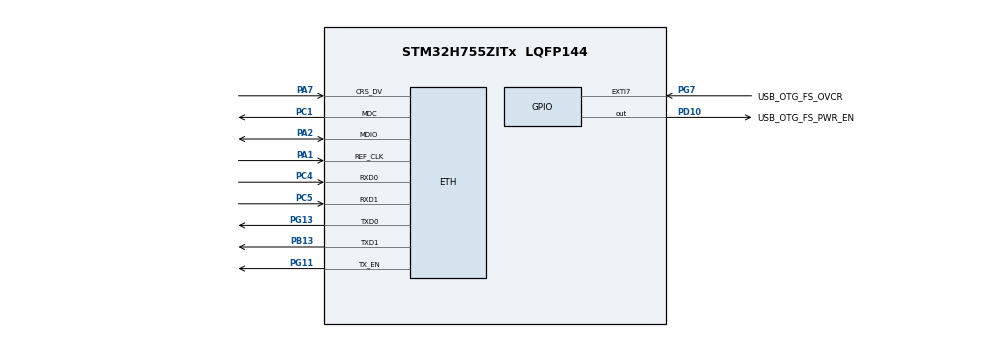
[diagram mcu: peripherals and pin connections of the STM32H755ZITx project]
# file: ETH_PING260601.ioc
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CortexM4.IPs=FATFS_M4\:I,FREERTOS_M4\:I,IWDG2\:I,RCC,WWDG2\:I,DMA,BDMA,MDMA,NVIC2\:I,ETH\:I,DEBUG,PDM2PCM_M4\:I,PWR,RESMGR_UTILITY,SYS_M4\:I,USB_DEVICE_M4\:I,USB_HOST_M4\:I,CORTEX_M4\:I,GPIO,OPENAMP_M4\:I,VREFBUF,NUCLEO-H755ZI-Q,LWIP\:I
CortexM7.IPs=FATFS_M7\:I,FREERTOS_M7\:I,IWDG1\:I,RCC\:I,WWDG1\:I,DMA\:I,BDMA\:I,MDMA\:I,NVIC1\:I,USB_OTG_FS\:I,USB_OTG_FS1\:I,SYS\:I,CORTEX_M7\:I,DEBUG\:I,PDM2PCM_M7\:I,PWR\:I,RESMGR_UTILITY\:I,USB_DEVICE_M7\:I,USB_HOST_M7\:I,GPIO\:I,OPENAMP_M7\:I,VREFBUF\:I,NUCLEO-H755ZI-Q\:I
ETH.MediaInterface=HAL_ETH_RMII_MODE
LWIP.BSP.number=1
LWIP.GATEWAY_ADDRESS=192.168.088.001
LWIP.IP_ADDRESS=192.168.088.010
LWIP.LWIP_DHCP=0
LWIP.NETMASK_ADDRESS=255.255.255.000
LWIP.TCP_MSS=1460
LWIP.TCP_SND_QUEUELEN=16
LWIP.Version=v2.2.1_Cube
LWIP0.BSP.STBoard=false
LWIP0.BSP.api=BSP_COMPONENT_DRIVER
LWIP0.BSP.component=LAN8742
LWIP0.BSP.instance=LAN8742
LWIP0.BSP.name=Driver_PHY
LWIP0.BSP.semaphore=S_LAN8742
LWIP0.BSP.solution=LAN8742
Mcu.Family=STM32H7
Mcu.Name=STM32H755ZITx
Mcu.Package=LQFP144
NUCLEO-H755ZI-Q.BUTTON=1
NUCLEO-H755ZI-Q.LD1=true
NUCLEO-H755ZI-Q.LD2=true
NUCLEO-H755ZI-Q.LD3=true
NUCLEO-H755ZI-Q.VCP=true
NVIC1.EXTI15_10_IRQn=true\:0\:0\:false\:false\:true\:false\:true\:true
NVIC1.PriorityGroup=NVIC_PRIORITYGROUP_4
NVIC2.ETH_IRQn=true\:0\:0\:false\:false\:true\:true\:true\:true
NVIC2.PriorityGroup=NVIC_PRIORITYGROUP_4
PA1.GPIO_Speed_Default_HIGH=GPIO_SPEED_FREQ_VERY_HIGH
PA1.Mode=RMII
PA1.PinAttribute=CortexM4
PA1.Signal=ETH_REF_CLK
PA11.PinAttribute=CortexM7
PA11.Signal=USB_OTG_FS_DM
PA12.PinAttribute=CortexM7
PA12.Signal=USB_OTG_FS_DP
PA2.GPIO_Speed_Default_HIGH=GPIO_SPEED_FREQ_VERY_HIGH
PA2.Mode=RMII
PA2.PinAttribute=CortexM4
PA2.Signal=ETH_MDIO
PA7.GPIO_Speed_Default_HIGH=GPIO_SPEED_FREQ_VERY_HIGH
PA7.Mode=RMII
PA7.PinAttribute=CortexM4
PA7.Signal=ETH_CRS_DV
PA8.PinAttribute=CortexM7
PA8.Signal=USB_OTG_FS_SOF
PA9.PinAttribute=CortexM7
PA9.Signal=USB_OTG_FS_VBUS
PB13.GPIO_Speed_Default_HIGH=GPIO_SPEED_FREQ_VERY_HIGH
PB13.Mode=RMII
PB13.PinAttribute=CortexM4
PB13.Signal=ETH_TXD1
PC1.GPIO_Speed_Default_HIGH=GPIO_SPEED_FREQ_VERY_HIGH
PC1.Mode=RMII
PC1.PinAttribute=CortexM4
PC1.Signal=ETH_MDC
PC14-OSC32_IN\ (OSC32_IN).Mode=LSE-External-Oscillator
PC14-OSC32_IN\ (OSC32_IN).PinAttribute=Free
PC14-OSC32_IN\ (OSC32_IN).Signal=RCC_OSC32_IN
PC15-OSC32_OUT\ (OSC32_OUT).Mode=LSE-External-Oscillator
PC15-OSC32_OUT\ (OSC32_OUT).PinAttribute=Free
PC15-OSC32_OUT\ (OSC32_OUT).Signal=RCC_OSC32_OUT
PC4.GPIO_Speed_Default_HIGH=GPIO_SPEED_FREQ_VERY_HIGH
PC4.Mode=RMII
PC4.PinAttribute=CortexM4
PC4.Signal=ETH_RXD0
PC5.GPIO_Speed_Default_HIGH=GPIO_SPEED_FREQ_VERY_HIGH
PC5.Mode=RMII
PC5.PinAttribute=CortexM4
PC5.Signal=ETH_RXD1
PD10.GPIO_Label=USB_OTG_FS_PWR_EN
PD10.PinAttribute=Free
PD10.Signal=GPIO_Output
PD8.Signal=USART3_TX
PD9.Signal=USART3_RX
PG11.GPIO_Speed_Default_HIGH=GPIO_SPEED_FREQ_VERY_HIGH
PG11.Mode=RMII
PG11.PinAttribute=CortexM4
PG11.Signal=ETH_TX_EN
PG13.GPIO_Speed_Default_HIGH=GPIO_SPEED_FREQ_VERY_HIGH
PG13.Mode=RMII
PG13.PinAttribute=CortexM4
PG13.Signal=ETH_TXD0
PG7.GPIO_Label=USB_OTG_FS_OVCR
PG7.PinAttribute=Free
PG7.Signal=GPXTI7
PH0-OSC_IN\ (PH0).Mode=HSE-External-Clock-Source
PH0-OSC_IN\ (PH0).PinAttribute=Free
PH0-OSC_IN\ (PH0).Signal=RCC_OSC_IN
PH1-OSC_OUT\ (PH1).PinAttribute=Free
PH1-OSC_OUT\ (PH1).Signal=RCC_OSC_OUT
ProjectManager.HeapSize=M4-0x200,M7-0x200
ProjectManager.StackSize=M4-0x400,M7-0x400
ProjectManager.TargetToolchain=STM32CubeIDE
RCC.ADCFreq_Value=50390625
RCC.APB1Freq_Value=120000000
RCC.APB2Freq_Value=120000000
RCC.APB3Freq_Value=120000000
RCC.APB4Freq_Value=120000000
RCC.CortexFreq_Value=120000000
RCC.DIVM1=5
RCC.DIVN1=48
RCC.DIVQ1=5
RCC.HCLKFreq_Value=120000000
RCC.PLL2FRACN=0
RCC.PLL3FRACN=0
RCC.PLLFRACN=0
RCC.PLLSourceVirtual=RCC_PLLSOURCE_HSE
RCC.SYSCLKFreq_VALUE=120000000
RCC.SYSCLKSource=RCC_SYSCLKSOURCE_PLLCLK
RCC.SupplySource=PWR_DIRECT_SMPS_SUPPLY
RCC.USBFreq_Value=48000000
VP_LWIP_VS_Enabled.Mode=Enabled
VP_NUCLEO-H755ZI-Q_VS_BSP_COMMON.Mode=COMMON
VP_SYS_M4_VS_Systick.Mode=SysTick
board=NUCLEO-H755ZI-Q

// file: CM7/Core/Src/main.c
/* USER CODE BEGIN Header */
/**
  ******************************************************************************
  * @file           : main.c
  * @brief          : Main program body
  ******************************************************************************
  * @attention
  *
  * Copyright (c) 2026 STMicroelectronics.
  * All rights reserved.
  *
  * This software is licensed under terms that can be found in the LICENSE file
  * in the root directory of this software component.
  * If no LICENSE file comes with this software, it is provided AS-IS.
  *
  ******************************************************************************
  */
/* USER CODE END Header */
#include "main.h"

/* USER CODE BEGIN PD */

/* DUAL_CORE_BOOT_SYNC_SEQUENCE: Define for dual core boot synchronization    */
/*                             demonstration code based on hardware semaphore */
/* This define is present in both CM7/CM4 projects                            */
/* To comment when developping/debugging on a single core                     */
#define DUAL_CORE_BOOT_SYNC_SEQUENCE

#if defined(DUAL_CORE_BOOT_SYNC_SEQUENCE)
#ifndef HSEM_ID_0
#define HSEM_ID_0 (0U) /* HW semaphore 0*/
#endif
#endif /* DUAL_CORE_BOOT_SYNC_SEQUENCE */

/* USER CODE END PD */

COM_InitTypeDef BspCOMInit;

void SystemClock_Config(void);
static void MX_GPIO_Init(void);

int main(void)
{

/* USER CODE BEGIN Boot_Mode_Sequence_0 */
#if defined(DUAL_CORE_BOOT_SYNC_SEQUENCE)
  int32_t timeout;
#endif /* DUAL_CORE_BOOT_SYNC_SEQUENCE */
/* USER CODE END Boot_Mode_Sequence_0 */

/* USER CODE BEGIN Boot_Mode_Sequence_1 */
#if defined(DUAL_CORE_BOOT_SYNC_SEQUENCE)
  /* Wait until CPU2 boots and enters in stop mode or timeout*/
  timeout = 0xFFFF;
  while((__HAL_RCC_GET_FLAG(RCC_FLAG_D2CKRDY) != RESET) && (timeout-- > 0));
  if ( timeout < 0 )
  {
  Error_Handler();
  }
#endif /* DUAL_CORE_BOOT_SYNC_SEQUENCE */
/* USER CODE END Boot_Mode_Sequence_1 */
  /* MCU Configuration--------------------------------------------------------*/

  /* Reset of all peripherals, Initializes the Flash interface and the Systick. */
  HAL_Init();

  /* USER CODE BEGIN Init */
  //SCB_EnableICache();
  //SCB_EnableDCache();
  /* USER CODE END Init */

  /* Configure the system clock */
  SystemClock_Config();
/* USER CODE BEGIN Boot_Mode_Sequence_2 */
#if defined(DUAL_CORE_BOOT_SYNC_SEQUENCE)
/* When system initialization is finished, Cortex-M7 will release Cortex-M4 by means of
HSEM notification */
/*HW semaphore Clock enable*/
__HAL_RCC_HSEM_CLK_ENABLE();
/*Take HSEM */
HAL_HSEM_FastTake(HSEM_ID_0);
/*Release HSEM in order to notify the CPU2(CM4)*/
HAL_HSEM_Release(HSEM_ID_0,0);
/* wait until CPU2 wakes up from stop mode */
timeout = 0xFFFF;
while((__HAL_RCC_GET_FLAG(RCC_FLAG_D2CKRDY) == RESET) && (timeout-- > 0));
if ( timeout < 0 )
{
Error_Handler();
}
#endif /* DUAL_CORE_BOOT_SYNC_SEQUENCE */
/* USER CODE END Boot_Mode_Sequence_2 */

  /* USER CODE BEGIN SysInit */

  // 喚醒 Cortex-M4 核心
  HAL_PWREx_ReleaseCore(PWR_CORE_CPU2);// 這是重點
  /* USER CODE END SysInit */

  /* Initialize all configured peripherals */
  MX_GPIO_Init();

  /* Initialize leds */
  //BSP_LED_Init(LED_GREEN); //由 CM4 自己控制 LED  2026-06-02 09:46:01
  //BSP_LED_Init(LED_YELLOW);
  //BSP_LED_Init(LED_RED);

  /* Initialize USER push-button, will be used to trigger an interrupt each time it's pressed.*/
  BSP_PB_Init(BUTTON_USER, BUTTON_MODE_EXTI);

  /* Initialize COM1 port (115200, 8 bits (7-bit data + 1 stop bit), no parity */
  BspCOMInit.BaudRate   = 115200;
  BspCOMInit.WordLength = COM_WORDLENGTH_8B;
  BspCOMInit.StopBits   = COM_STOPBITS_1;
  BspCOMInit.Parity     = COM_PARITY_NONE;
  BspCOMInit.HwFlowCtl  = COM_HWCONTROL_NONE;
  if (BSP_COM_Init(COM1, &BspCOMInit) != BSP_ERROR_NONE)
  {
    Error_Handler();
  }

  /* ------------------ CRITICAL MODIFICATION BEGIN ------------------ */

  // 1. 啟用 SYSCFG 時脈（SYSCFG 位於 APB4 總線，控制了全晶片的引腳網路模式切換）
  __HAL_RCC_SYSCFG_CLK_ENABLE();

  // 2. 強制將乙太網路硬體介面切換為 RMII 模式。
  //    這行硬體設定必須在 CM4 核心啟動並初始化網路之前，由 CM7 先行在底層組態完成！
  HAL_SYSCFG_ETHInterfaceSelect(SYSCFG_ETH_RMII);

  /* ------------------- CRITICAL MODIFICATION END ------------------- */

  /* Infinite loop */
  while (1)
  {

  }
}

void SystemClock_Config(void)
{
  RCC_OscInitTypeDef RCC_OscInitStruct = {0};
  RCC_ClkInitTypeDef RCC_ClkInitStruct = {0};

  /** Supply configuration update enable
  */
  HAL_PWREx_ConfigSupply(PWR_DIRECT_SMPS_SUPPLY);

  /** Configure the main internal regulator output voltage
  */
  __HAL_PWR_VOLTAGESCALING_CONFIG(PWR_REGULATOR_VOLTAGE_SCALE3);

  while(!__HAL_PWR_GET_FLAG(PWR_FLAG_VOSRDY)) {}

  /** Initializes the RCC Oscillators according to the specified parameters
  * in the RCC_OscInitTypeDef structure.
  */
  RCC_OscInitStruct.OscillatorType = RCC_OSCILLATORTYPE_HSE;
  RCC_OscInitStruct.HSEState = RCC_HSE_BYPASS;
  RCC_OscInitStruct.PLL.PLLState = RCC_PLL_ON;
  RCC_OscInitStruct.PLL.PLLSource = RCC_PLLSOURCE_HSE;
  RCC_OscInitStruct.PLL.PLLM = 5;
  RCC_OscInitStruct.PLL.PLLN = 48;
  RCC_OscInitStruct.PLL.PLLP = 2;
  RCC_OscInitStruct.PLL.PLLQ = 5;
  RCC_OscInitStruct.PLL.PLLR = 2;
  RCC_OscInitStruct.PLL.PLLRGE = RCC_PLL1VCIRANGE_2;
  RCC_OscInitStruct.PLL.PLLVCOSEL = RCC_PLL1VCOWIDE;
  RCC_OscInitStruct.PLL.PLLFRACN = 0;
  if (HAL_RCC_OscConfig(&RCC_OscInitStruct) != HAL_OK)
  {
    Error_Handler();
  }

  /** Initializes the CPU, AHB and APB buses clocks
  */
  RCC_ClkInitStruct.ClockType = RCC_CLOCKTYPE_HCLK|RCC_CLOCKTYPE_SYSCLK
                              |RCC_CLOCKTYPE_PCLK1|RCC_CLOCKTYPE_PCLK2
                              |RCC_CLOCKTYPE_D3PCLK1|RCC_CLOCKTYPE_D1PCLK1;
  RCC_ClkInitStruct.SYSCLKSource = RCC_SYSCLKSOURCE_PLLCLK;
  RCC_ClkInitStruct.SYSCLKDivider = RCC_SYSCLK_DIV1;
  RCC_ClkInitStruct.AHBCLKDivider = RCC_HCLK_DIV1;
  RCC_ClkInitStruct.APB3CLKDivider = RCC_APB3_DIV1;
  RCC_ClkInitStruct.APB1CLKDivider = RCC_APB1_DIV1;
  RCC_ClkInitStruct.APB2CLKDivider = RCC_APB2_DIV1;
  RCC_ClkInitStruct.APB4CLKDivider = RCC_APB4_DIV1;

  if (HAL_RCC_ClockConfig(&RCC_ClkInitStruct, FLASH_LATENCY_2) != HAL_OK)
  {
    Error_Handler();
  }
}

static void MX_GPIO_Init(void)
{
  GPIO_InitTypeDef GPIO_InitStruct = {0};

  /* GPIO Ports Clock Enable */
  __HAL_RCC_GPIOA_CLK_ENABLE();

  /*Configure GPIO pins : PA8 PA11 PA12 */
  GPIO_InitStruct.Pin = GPIO_PIN_8|GPIO_PIN_11|GPIO_PIN_12;
  GPIO_InitStruct.Mode = GPIO_MODE_AF_PP;
  GPIO_InitStruct.Pull = GPIO_NOPULL;
  GPIO_InitStruct.Speed = GPIO_SPEED_FREQ_LOW;
  GPIO_InitStruct.Alternate = GPIO_AF10_OTG1_FS;
  HAL_GPIO_Init(GPIOA, &GPIO_InitStruct);

}

void Error_Handler(void)
{
  __disable_irq();
  while (1)
  {
  }
}
